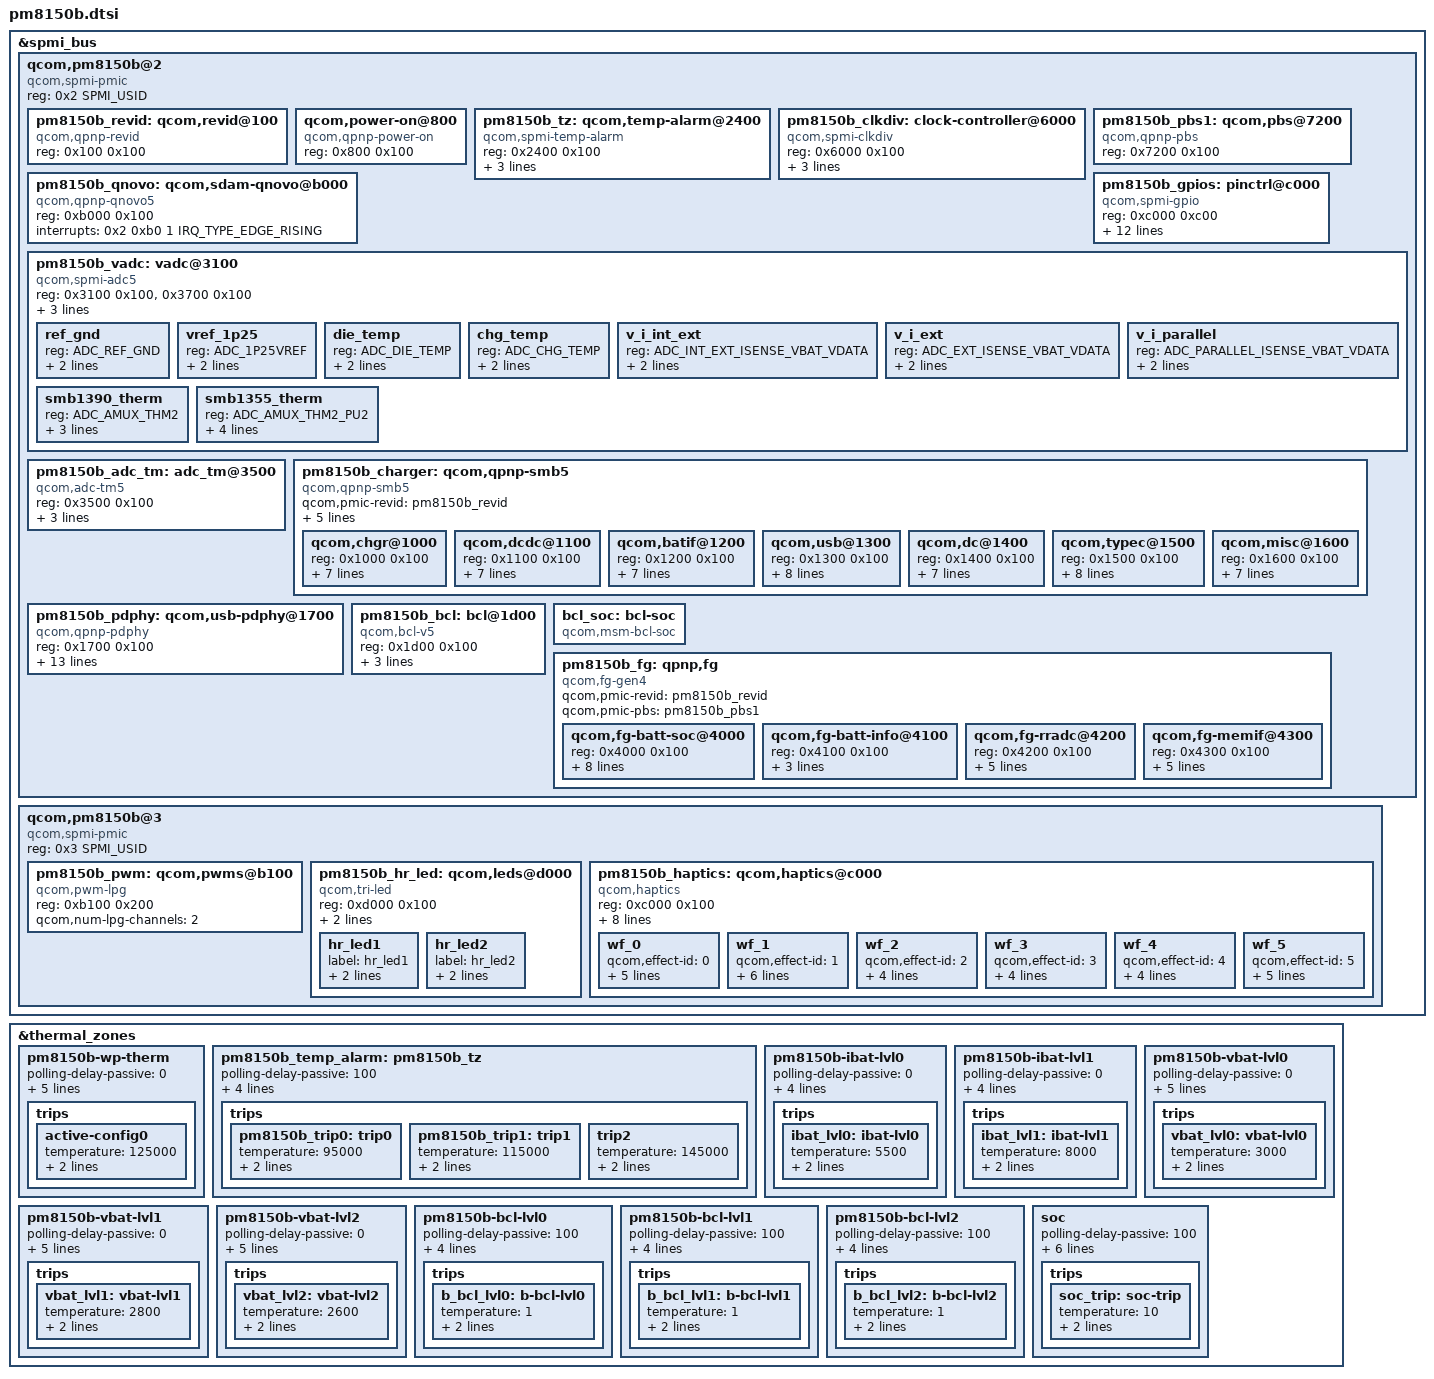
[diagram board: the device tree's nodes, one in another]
/*
 * Copyright (c) 2017-2019, The Linux Foundation. All rights reserved.
 * Copyright (C) 2021 XiaoMi, Inc.
 *
 * This program is free software; you can redistribute it and/or modify
 * it under the terms of the GNU General Public License version 2 and
 * only version 2 as published by the Free Software Foundation.
 *
 * This program is distributed in the hope that it will be useful,
 * but WITHOUT ANY WARRANTY; without even the implied warranty of
 * MERCHANTABILITY or FITNESS FOR A PARTICULAR PURPOSE.  See the
 * GNU General Public License for more details.
 */

#include <dt-bindings/spmi/spmi.h>
#include <dt-bindings/interrupt-controller/irq.h>
#include <dt-bindings/iio/qcom,spmi-vadc.h>

&spmi_bus {
	#address-cells = <2>;
	#size-cells = <0>;

	qcom,pm8150b@2 {
		compatible = "qcom,spmi-pmic";
		reg = <0x2 SPMI_USID>;
		#address-cells = <2>;
		#size-cells = <0>;

		pm8150b_revid: qcom,revid@100 {
			compatible = "qcom,qpnp-revid";
			reg = <0x100 0x100>;
		};

		qcom,power-on@800 {
			compatible = "qcom,qpnp-power-on";
			reg = <0x800 0x100>;
		};

		pm8150b_tz: qcom,temp-alarm@2400 {
			compatible = "qcom,spmi-temp-alarm";
			reg = <0x2400 0x100>;
			interrupts = <0x2 0x24 0x0 IRQ_TYPE_EDGE_RISING>;
			io-channels = <&pm8150b_vadc ADC_DIE_TEMP>;
			io-channel-names = "thermal";
			#thermal-sensor-cells = <0>;
			qcom,temperature-threshold-set = <1>;
		};

		pm8150b_clkdiv: clock-controller@6000 {
			compatible = "qcom,spmi-clkdiv";
			reg = <0x6000 0x100>;
			#clock-cells = <1>;
			qcom,num-clkdivs = <1>;
			clock-output-names = "pm8150b_div_clk1";
			clocks = <&clock_rpmh RPMH_CXO_CLK>;
			clock-names = "xo";
		};

		pm8150b_pbs1: qcom,pbs@7200 {
			compatible = "qcom,qpnp-pbs";
			reg = <0x7200 0x100>;
		};

		pm8150b_qnovo: qcom,sdam-qnovo@b000 {
			compatible = "qcom,qpnp-qnovo5";
			reg = <0xb000 0x100>;
			interrupts = <0x2 0xb0 1 IRQ_TYPE_EDGE_RISING>;
			interrupt-names = "ptrain-done";
		};

		pm8150b_gpios: pinctrl@c000 {
			compatible = "qcom,spmi-gpio";
			reg = <0xc000 0xc00>;
			interrupts = <0x2 0xc0 0 IRQ_TYPE_NONE>,
					<0x2 0xc1 0 IRQ_TYPE_NONE>,
					<0x2 0xc4 0 IRQ_TYPE_NONE>,
					<0x2 0xc5 0 IRQ_TYPE_NONE>,
					<0x2 0xc6 0 IRQ_TYPE_NONE>,
					<0x2 0xc7 0 IRQ_TYPE_NONE>,
					<0x2 0xc8 0 IRQ_TYPE_NONE>,
					<0x2 0xc9 0 IRQ_TYPE_NONE>,
					<0x2 0xca 0 IRQ_TYPE_NONE>,
					<0x2 0xcb 0 IRQ_TYPE_NONE>;
			interrupt-names = "pm8150b_gpio1", "pm8150b_gpio2",
					"pm8150b_gpio5", "pm8150b_gpio6",
					"pm8150b_gpio7", "pm8150b_gpio8",
					"pm8150b_gpio9", "pm8150b_gpio10",
					"pm8150b_gpio11", "pm8150b_gpio12";
			gpio-controller;
			#gpio-cells = <2>;
			qcom,gpios-disallowed = <3 4>;
		};

		pm8150b_vadc: vadc@3100 {
			compatible = "qcom,spmi-adc5";
			reg = <0x3100 0x100>, <0x3700 0x100>;
			reg-names = "adc5-usr-base", "adc5-cal-base";
			#address-cells = <1>;
			#size-cells = <0>;
			interrupts = <0x2 0x31 0x0 IRQ_TYPE_EDGE_RISING>;
			interrupt-names = "eoc-int-en-set";
			qcom,adc-vdd-reference = <1875>;
			#io-channel-cells = <1>;
			io-channel-ranges;

			/* Channel node */
			ref_gnd {
				reg = <ADC_REF_GND>;
				label = "ref_gnd";
				qcom,pre-scaling = <1 1>;
			};

			vref_1p25 {
				reg = <ADC_1P25VREF>;
				label = "vref_1p25";
				qcom,pre-scaling = <1 1>;
			};

			die_temp {
				reg = <ADC_DIE_TEMP>;
				label = "die_temp";
				qcom,pre-scaling = <1 1>;
			};

			chg_temp {
				reg = <ADC_CHG_TEMP>;
				label = "chg_temp";
				qcom,pre-scaling = <1 1>;
			};

			v_i_int_ext {
				reg = <ADC_INT_EXT_ISENSE_VBAT_VDATA>;
				label = "v_i_int_vbat_vdata";
				qcom,pre-scaling = <1 1>;
			};

			v_i_ext {
				reg = <ADC_EXT_ISENSE_VBAT_VDATA>;
				label = "v_i_int_ext_vbat_vdata";
				qcom,pre-scaling = <1 1>;
			};

			v_i_parallel {
				reg = <ADC_PARALLEL_ISENSE_VBAT_VDATA>;
				label = "v_i_parallel_vbat_vdata";
				qcom,pre-scaling = <1 1>;
			};

			smb1390_therm {
				reg = <ADC_AMUX_THM2>;
				label = "smb1390_therm";
				qcom,hw-settle-time = <200>;
				qcom,pre-scaling = <1 1>;
			};

			smb1355_therm {
				reg = <ADC_AMUX_THM2_PU2>;
				label = "smb1355_therm";
				qcom,ratiometric;
				qcom,hw-settle-time = <200>;
				qcom,pre-scaling = <1 1>;
			};
		};

		pm8150b_adc_tm: adc_tm@3500 {
			compatible = "qcom,adc-tm5";
			reg = <0x3500 0x100>;
			interrupts = <0x2 0x35 0x0 IRQ_TYPE_EDGE_RISING>;
			interrupt-names = "thr-int-en";
			#address-cells = <1>;
			#size-cells = <0>;
			#thermal-sensor-cells = <1>;
			io-channels = <&pm8150b_vadc ADC_AMUX_THM1_PU2>;
			qcom,pmic-revid = <&pm8150b_revid>;
		};

		pm8150b_charger: qcom,qpnp-smb5 {
			compatible = "qcom,qpnp-smb5";
			#address-cells = <1>;
			#size-cells = <1>;
			#cooling-cells = <2>;

			qcom,pmic-revid = <&pm8150b_revid>;

			qcom,thermal-mitigation
					= <3000000 1500000 1000000 500000>;

			qcom,chg-term-src = <1>;
			qcom,charger-temp-max = <800>;
			qcom,smb-temp-max = <800>;

			qcom,chgr@1000 {
				reg = <0x1000 0x100>;
				interrupts =
					<0x2 0x10 0x0 IRQ_TYPE_EDGE_RISING>,
					<0x2 0x10 0x1 IRQ_TYPE_EDGE_RISING>,
					<0x2 0x10 0x2 IRQ_TYPE_EDGE_RISING>,
					<0x2 0x10 0x3 IRQ_TYPE_EDGE_RISING>,
					<0x2 0x10 0x4 IRQ_TYPE_EDGE_RISING>,
					<0x2 0x10 0x6 IRQ_TYPE_EDGE_BOTH>,
					<0x2 0x10 0x7 IRQ_TYPE_EDGE_BOTH>;

				interrupt-names = "chgr-error",
						  "chg-state-change",
						  "step-chg-state-change",
						  "step-chg-soc-update-fail",
						  "step-chg-soc-update-req",
						  "vph-alarm",
						  "vph-drop-prechg";
			};

			qcom,dcdc@1100 {
				reg = <0x1100 0x100>;
				interrupts =
					<0x2 0x11 0x0 IRQ_TYPE_EDGE_BOTH>,
					<0x2 0x11 0x1 IRQ_TYPE_EDGE_BOTH>,
					<0x2 0x11 0x2 IRQ_TYPE_EDGE_BOTH>,
					<0x2 0x11 0x4 IRQ_TYPE_EDGE_BOTH>,
					<0x2 0x11 0x5 IRQ_TYPE_EDGE_BOTH>,
					<0x2 0x11 0x6 IRQ_TYPE_EDGE_BOTH>,
					<0x2 0x11 0x7 IRQ_TYPE_EDGE_BOTH>;

				interrupt-names = "otg-fail",
						  "otg-oc-disable-sw",
						  "otg-oc-hiccup",
						  "high-duty-cycle",
						  "input-current-limiting",
						  "concurrent-mode-disable",
						  "switcher-power-ok";
			};

			qcom,batif@1200 {
				reg = <0x1200 0x100>;
				interrupts =
					<0x2 0x12 0x0 IRQ_TYPE_EDGE_RISING>,
					<0x2 0x12 0x2 IRQ_TYPE_EDGE_BOTH>,
					<0x2 0x12 0x3 IRQ_TYPE_EDGE_BOTH>,
					<0x2 0x12 0x4 IRQ_TYPE_EDGE_BOTH>,
					<0x2 0x12 0x5 IRQ_TYPE_EDGE_BOTH>,
					<0x2 0x12 0x6 IRQ_TYPE_EDGE_BOTH>,
					<0x2 0x12 0x7 IRQ_TYPE_EDGE_BOTH>;

				interrupt-names = "bat-temp",
						  "bat-ov",
						  "bat-low",
						  "bat-therm-or-id-missing",
						  "bat-terminal-missing",
						  "buck-oc",
						  "vph-ov";
			};

			qcom,usb@1300 {
				reg = <0x1300 0x100>;
				interrupts =
					<0x2 0x13 0x0 IRQ_TYPE_EDGE_BOTH>,
					<0x2 0x13 0x1 IRQ_TYPE_EDGE_BOTH>,
					<0x2 0x13 0x2 IRQ_TYPE_EDGE_BOTH>,
					<0x2 0x13 0x3 IRQ_TYPE_EDGE_BOTH>,
					<0x2 0x13 0x4 IRQ_TYPE_EDGE_BOTH>,
					<0x2 0x13 0x5 IRQ_TYPE_EDGE_BOTH>,
					<0x2 0x13 0x6 IRQ_TYPE_EDGE_RISING>,
					<0x2 0x13 0x7 IRQ_TYPE_EDGE_RISING>;

				interrupt-names = "usbin-collapse",
						  "usbin-vashdn",
						  "usbin-uv",
						  "usbin-ov",
						  "usbin-plugin",
						  "usbin-revi-change",
						  "usbin-src-change",
						  "usbin-icl-change";
			};

			qcom,dc@1400 {
				reg = <0x1400 0x100>;
				interrupts =
					<0x2 0x14 0x1 IRQ_TYPE_EDGE_BOTH>,
					<0x2 0x14 0x2 IRQ_TYPE_EDGE_BOTH>,
					<0x2 0x14 0x3 IRQ_TYPE_EDGE_BOTH>,
					<0x2 0x14 0x4 IRQ_TYPE_EDGE_BOTH>,
					<0x2 0x14 0x5 IRQ_TYPE_EDGE_BOTH>,
					<0x2 0x14 0x6 IRQ_TYPE_EDGE_BOTH>,
					<0x2 0x14 0x7 IRQ_TYPE_EDGE_BOTH>;

				interrupt-names = "dcin-vashdn",
						  "dcin-uv",
						  "dcin-ov",
						  "dcin-plugin",
						  "dcin-revi",
						  "dcin-pon",
						  "dcin-en";
			};

			qcom,typec@1500 {
				reg = <0x1500 0x100>;
				interrupts =
					<0x2 0x15 0x0 IRQ_TYPE_EDGE_RISING>,
					<0x2 0x15 0x1 IRQ_TYPE_EDGE_BOTH>,
					<0x2 0x15 0x2 IRQ_TYPE_EDGE_RISING>,
					<0x2 0x15 0x3 IRQ_TYPE_EDGE_BOTH>,
					<0x2 0x15 0x4 IRQ_TYPE_EDGE_RISING>,
					<0x2 0x15 0x5 IRQ_TYPE_EDGE_RISING>,
					<0x2 0x15 0x6 IRQ_TYPE_EDGE_BOTH>,
					<0x2 0x15 0x7 IRQ_TYPE_EDGE_RISING>;

				interrupt-names = "typec-or-rid-detect-change",
						  "typec-vpd-detect",
						  "typec-cc-state-change",
						  "typec-vconn-oc",
						  "typec-vbus-change",
						  "typec-attach-detach",
						  "typec-legacy-cable-detect",
						  "typec-try-snk-src-detect";
			};

			qcom,misc@1600 {
				reg = <0x1600 0x100>;
				interrupts =
					<0x2 0x16 0x0 IRQ_TYPE_EDGE_RISING>,
					<0x2 0x16 0x1 IRQ_TYPE_EDGE_RISING>,
					<0x2 0x16 0x2 IRQ_TYPE_EDGE_BOTH>,
					<0x2 0x16 0x3 IRQ_TYPE_EDGE_BOTH>,
					<0x2 0x16 0x4 IRQ_TYPE_EDGE_BOTH>,
					<0x2 0x16 0x6 IRQ_TYPE_EDGE_BOTH>,
					<0x2 0x16 0x7 IRQ_TYPE_EDGE_BOTH>;

				interrupt-names = "wdog-snarl",
						  "wdog-bark",
						  "aicl-fail",
						  "aicl-done",
						  "smb-en",
						  "temp-change",
						  "temp-change-smb";
			};
		};

		pm8150b_pdphy: qcom,usb-pdphy@1700 {
			compatible = "qcom,qpnp-pdphy";
			reg = <0x1700 0x100>;
			vdd-pdphy-supply = <&pm8150_l2>;
			vbus-supply = <&smb5_vbus>;
			vconn-supply = <&smb5_vconn>;
			interrupts = <0x2 0x17 0x0 IRQ_TYPE_EDGE_RISING>,
				     <0x2 0x17 0x1 IRQ_TYPE_EDGE_RISING>,
				     <0x2 0x17 0x2 IRQ_TYPE_EDGE_RISING>,
				     <0x2 0x17 0x3 IRQ_TYPE_EDGE_RISING>,
				     <0x2 0x17 0x4 IRQ_TYPE_EDGE_RISING>,
				     <0x2 0x17 0x5 IRQ_TYPE_EDGE_RISING>,
				     <0x2 0x17 0x6 IRQ_TYPE_EDGE_RISING>,
				     <0x2 0x17 0x7 IRQ_TYPE_EDGE_RISING>;

			interrupt-names = "sig-tx",
					  "sig-rx",
					  "msg-tx",
					  "msg-rx",
					  "msg-tx-failed",
					  "msg-tx-discarded",
					  "msg-rx-discarded",
					  "fr-swap";

			qcom,default-sink-caps = <5000 3000>, /* 5V @ 3A */
						 <9000 3000>, /* 9V @ 3A */
						 <12000 2250>; /* 12V @ 2.25A */
		};

		pm8150b_bcl: bcl@1d00 {
			compatible = "qcom,bcl-v5";
			reg = <0x1d00 0x100>;
			interrupts = <0x2 0x1d 0x0 IRQ_TYPE_NONE>,
					<0x2 0x1d 0x1 IRQ_TYPE_NONE>,
					<0x2 0x1d 0x2 IRQ_TYPE_NONE>;
			interrupt-names = "bcl-lvl0",
						"bcl-lvl1",
						"bcl-lvl2";
			#thermal-sensor-cells = <1>;
		};

		bcl_soc:bcl-soc {
			compatible = "qcom,msm-bcl-soc";
			#thermal-sensor-cells = <0>;
		};

		pm8150b_fg: qpnp,fg {
			compatible = "qcom,fg-gen4";
			#address-cells = <1>;
			#size-cells = <1>;
			qcom,pmic-revid = <&pm8150b_revid>;
			qcom,pmic-pbs = <&pm8150b_pbs1>;
			status = "okay";

			qcom,fg-batt-soc@4000 {
				status = "okay";
				reg = <0x4000 0x100>;
				interrupts = <0x2 0x40 0x0 IRQ_TYPE_EDGE_BOTH>,
					     <0x2 0x40 0x1 IRQ_TYPE_EDGE_BOTH>,
					     <0x2 0x40 0x2
							IRQ_TYPE_EDGE_RISING>,
					     <0x2 0x40 0x3
							IRQ_TYPE_EDGE_RISING>,
					     <0x2 0x40 0x4 IRQ_TYPE_EDGE_BOTH>,
					     <0x2 0x40 0x5
							IRQ_TYPE_EDGE_RISING>,
					     <0x2 0x40 0x6 IRQ_TYPE_EDGE_BOTH>,
					     <0x2 0x40 0x7 IRQ_TYPE_EDGE_BOTH>;
				interrupt-names = "soc-update",
						  "soc-ready",
						  "bsoc-delta",
						  "msoc-delta",
						  "msoc-low",
						  "msoc-empty",
						  "msoc-high",
						  "msoc-full";
			};

			qcom,fg-batt-info@4100 {
				status = "okay";
				reg = <0x4100 0x100>;
				interrupts = <0x2 0x41 0x0 IRQ_TYPE_EDGE_BOTH>,
					     <0x2 0x41 0x1 IRQ_TYPE_EDGE_BOTH>,
					     <0x2 0x41 0x3
							IRQ_TYPE_EDGE_RISING>;
				interrupt-names = "vbatt-low",
						  "vbatt-pred-delta",
						  "esr-delta";
			};

			qcom,fg-rradc@4200 {
				status = "okay";
				reg = <0x4200 0x100>;
				interrupts = <0x2 0x42 0x0 IRQ_TYPE_EDGE_BOTH>,
					     <0x2 0x42 0x1 IRQ_TYPE_EDGE_BOTH>,
					     <0x2 0x42 0x2 IRQ_TYPE_EDGE_BOTH>,
					     <0x2 0x42 0x3 IRQ_TYPE_EDGE_BOTH>,
					     <0x2 0x42 0x4 IRQ_TYPE_EDGE_BOTH>;
				interrupt-names = "batt-missing",
						  "batt-id",
						  "batt-temp-delta",
						  "batt-temp-hot",
						  "batt-temp-cold";
			};

			qcom,fg-memif@4300 {
				status = "okay";
				reg = <0x4300 0x100>;
				interrupts = <0x2 0x43 0x0 IRQ_TYPE_EDGE_BOTH>,
					     <0x2 0x43 0x1 IRQ_TYPE_EDGE_BOTH>,
					     <0x2 0x43 0x2 IRQ_TYPE_EDGE_BOTH>,
					     <0x2 0x43 0x3
							IRQ_TYPE_EDGE_RISING>,
					     <0x2 0x43 0x4
							IRQ_TYPE_EDGE_FALLING>;
				interrupt-names = "ima-rdy",
						  "ima-xcp",
						  "dma-xcp",
						  "dma-grant",
						  "mem-attn";
			};
		};
	};

	qcom,pm8150b@3 {
		compatible ="qcom,spmi-pmic";
		reg = <0x3 SPMI_USID>;
		#address-cells = <2>;
		#size-cells = <0>;

		pm8150b_pwm: qcom,pwms@b100 {
			compatible = "qcom,pwm-lpg";
			reg = <0xb100 0x200>;
			reg-names = "lpg-base";
			#pwm-cells = <2>;
			qcom,num-lpg-channels = <2>;
		};

		pm8150b_hr_led: qcom,leds@d000 {
			compatible = "qcom,tri-led";
			reg = <0xd000 0x100>;
			nvmem-names = "pbs_sdam";
			nvmem = <&pm8150_sdam_2>;
			hr_led1 {
				label = "hr_led1";
				pwms = <&pm8150b_pwm 0 1000000>;
				led-sources = <0>;
			};
			hr_led2 {
				label = "hr_led2";
				pwms = <&pm8150b_pwm 1 1000000>;
				led-sources = <1>;
			};
		};

		pm8150b_haptics: qcom,haptics@c000 {
			compatible = "qcom,haptics";
			reg = <0xc000 0x100>;
			interrupts = <0x3 0xc0 0x0 IRQ_TYPE_EDGE_BOTH>,
				     <0x3 0xc0 0x1 IRQ_TYPE_EDGE_BOTH>;
			interrupt-names = "hap-sc-irq", "hap-play-irq";
			qcom,actuator-type = "lra";
			qcom,vmax-mv = <3400>;
			qcom,play-rate-us = <6667>;
			qcom,lra-resonance-sig-shape = "sine";
			qcom,lra-auto-resonance-mode = "qwd";
			qcom,lra-allow-variable-play-rate;

			wf_0 {
				/* CLICK */
				qcom,effect-id = <0>;
				qcom,wf-vmax-mv = <3600>;
				qcom,wf-pattern = [3e 3e 3e];
				qcom,wf-play-rate-us = <6667>;
				qcom,wf-brake-pattern = [01 00 00 00];
				qcom,lra-auto-resonance-disable;
			};
			wf_1 {
				/* DOUBLE CLICK */
				qcom,effect-id = <1>;
				qcom,wf-vmax-mv = <3600>;
				qcom,wf-pattern = [7e 7e 02 02 02 02 02 02];
				qcom,wf-play-rate-us = <7143>;
				qcom,wf-repeat-count = <2>;
				qcom,wf-s-repeat-count = <1>;
				qcom,lra-auto-resonance-disable;
			};
			wf_2 {
				/* TICK */
				qcom,effect-id = <2>;
				qcom,wf-vmax-mv = <3600>;
				qcom,wf-pattern = [7e 7e];
				qcom,wf-play-rate-us = <4000>;
				qcom,lra-auto-resonance-disable;
			};
			wf_3 {
				/* THUD */
				qcom,effect-id = <3>;
				qcom,wf-vmax-mv = <3600>;
				qcom,wf-pattern = [7e 7e 7e];
				qcom,wf-play-rate-us = <6667>;
				qcom,lra-auto-resonance-disable;
			};
			wf_4 {
				/* POP */
				qcom,effect-id = <4>;
				qcom,wf-vmax-mv = <3600>;
				qcom,wf-pattern = [7e 7e];
				qcom,wf-play-rate-us = <5000>;
				qcom,lra-auto-resonance-disable;
			};
			wf_5 {
				/* HEAVY CLICK */
				qcom,effect-id = <5>;
				qcom,wf-vmax-mv = <3600>;
				qcom,wf-pattern = [7e 7e 7e];
				qcom,wf-play-rate-us = <6667>;
				qcom,wf-brake-pattern = [03 00 00 00];
				qcom,lra-auto-resonance-disable;
			};
		};
	};
};

&thermal_zones {
	pm8150b-wp-therm {
		polling-delay-passive = <0>;
		polling-delay = <0>;
		thermal-governor = "user_space";
		thermal-sensors = <&pm8150b_adc_tm ADC_AMUX_THM2_PU2>;
		wake-capable-sensor;
		trips {
			active-config0 {
				temperature = <125000>;
				hysteresis = <1000>;
				type = "passive";
			};
		};
	};

	pm8150b_temp_alarm: pm8150b_tz {
		polling-delay-passive = <100>;
		polling-delay = <0>;
		thermal-governor = "step_wise";
		thermal-sensors = <&pm8150b_tz>;
		wake-capable-sensor;

		trips {
			pm8150b_trip0: trip0 {
				temperature = <95000>;
				hysteresis = <0>;
				type = "passive";
			};
			pm8150b_trip1: trip1 {
				temperature = <115000>;
				hysteresis = <0>;
				type = "passive";
			};
			trip2 {
				temperature = <145000>;
				hysteresis = <0>;
				type = "passive";
			};
		};
	};

	pm8150b-ibat-lvl0 {
		polling-delay-passive = <0>;
		polling-delay = <0>;
		thermal-governor = "step_wise";
		thermal-sensors = <&pm8150b_bcl 0>;
		wake-capable-sensor;

		trips {
			ibat_lvl0:ibat-lvl0 {
				temperature = <5500>;
				hysteresis = <200>;
				type = "passive";
			};
		};
	};

	pm8150b-ibat-lvl1 {
		polling-delay-passive = <0>;
		polling-delay = <0>;
		thermal-governor = "step_wise";
		thermal-sensors = <&pm8150b_bcl 1>;
		wake-capable-sensor;

		trips {
			ibat_lvl1:ibat-lvl1 {
				temperature = <8000>;
				hysteresis = <200>;
				type = "passive";
			};
		};
	};

	pm8150b-vbat-lvl0 {
		polling-delay-passive = <0>;
		polling-delay = <0>;
		thermal-governor = "low_limits_cap";
		thermal-sensors = <&pm8150b_bcl 2>;
		wake-capable-sensor;
		tracks-low;

		trips {
			vbat_lvl0: vbat-lvl0 {
				temperature = <3000>;
				hysteresis = <200>;
				type = "passive";
			};
		};
	};

	pm8150b-vbat-lvl1 {
		polling-delay-passive = <0>;
		polling-delay = <0>;
		thermal-governor = "low_limits_cap";
		thermal-sensors = <&pm8150b_bcl 3>;
		wake-capable-sensor;
		tracks-low;

		trips {
			vbat_lvl1:vbat-lvl1 {
				temperature = <2800>;
				hysteresis = <200>;
				type = "passive";
			};
		};
	};

	pm8150b-vbat-lvl2 {
		polling-delay-passive = <0>;
		polling-delay = <0>;
		thermal-governor = "low_limits_cap";
		thermal-sensors = <&pm8150b_bcl 4>;
		wake-capable-sensor;
		tracks-low;

		trips {
			vbat_lvl2:vbat-lvl2 {
				temperature = <2600>;
				hysteresis = <200>;
				type = "passive";
			};
		};
	};

	pm8150b-bcl-lvl0 {
		polling-delay-passive = <100>;
		polling-delay = <0>;
		thermal-governor = "step_wise";
		thermal-sensors = <&pm8150b_bcl 5>;
		wake-capable-sensor;

		trips {
			b_bcl_lvl0: b-bcl-lvl0 {
				temperature = <1>;
				hysteresis = <1>;
				type = "passive";
			};
		};
	};

	pm8150b-bcl-lvl1 {
		polling-delay-passive = <100>;
		polling-delay = <0>;
		thermal-governor = "step_wise";
		thermal-sensors = <&pm8150b_bcl 6>;
		wake-capable-sensor;

		trips {
			b_bcl_lvl1: b-bcl-lvl1 {
				temperature = <1>;
				hysteresis = <1>;
				type = "passive";
			};
		};
	};

	pm8150b-bcl-lvl2 {
		polling-delay-passive = <100>;
		polling-delay = <0>;
		thermal-governor = "step_wise";
		thermal-sensors = <&pm8150b_bcl 7>;
		wake-capable-sensor;

		trips {
			b_bcl_lvl2: b-bcl-lvl2 {
				temperature = <1>;
				hysteresis = <1>;
				type = "passive";
			};
		};
	};

	soc {
		polling-delay-passive = <100>;
		polling-delay = <0>;
		thermal-governor = "low_limits_cap";
		thermal-sensors = <&bcl_soc>;
		wake-capable-sensor;
		tracks-low;
		disable-thermal-zone;
		trips {
			soc_trip:soc-trip {
				temperature = <10>;
				hysteresis = <0>;
				type = "passive";
			};
		};
	};
};
